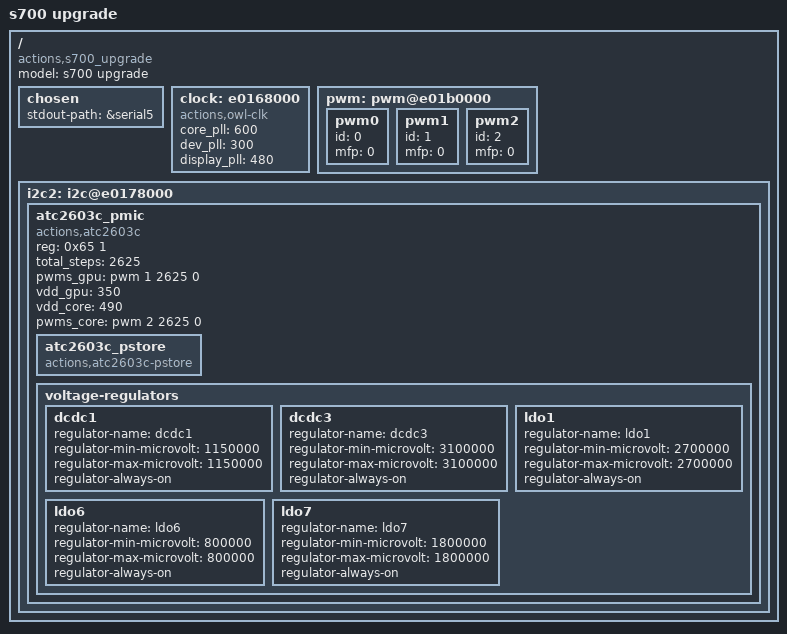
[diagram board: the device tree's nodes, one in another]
/*
 * Copyright (c) 2015 Actions Semi Co., Ltd.
 *
 * SPDX-License-Identifier:	GPL-2.0+
 */

/dts-v1/;

#include "s700.dtsi"

/ {
	model = "s700 upgrade";
	compatible = "actions,s700_upgrade", "actions,s700";

	chosen {
		stdout-path = &serial5;
	};

	clock:e0168000 {
		compatible = "actions,owl-clk";
		core_pll = <600>;
		dev_pll = <300>;
		display_pll = <480>;
	};

	pwm: pwm@e01b0000 {
		pwm0 {
			id = <0>;
			mfp = <0>;
		};

		pwm1 {
			id = <1>;
			mfp = <0>;
		};

		pwm2 {
			id = <2>;
			mfp = <0>;
		};
	};
	i2c2: i2c@e0178000 {
			#address-cells = <1>;
			#size-cells = <1>;
		atc2603c_pmic {
			compatible = "actions,atc2603c";
			reg = <0x65 1>;


			total_steps = <2625>;
			pwms_gpu = <&pwm 1 2625 0>;
			vdd_gpu = <350>;
			vdd_core = <490>;
			pwms_core = <&pwm 2 2625 0>;
			atc2603c_pstore {
					compatible = "actions,atc2603c-pstore";
			};
			voltage-regulators {

			dcdc1: dcdc1 {
				regulator-name = "dcdc1";
				regulator-min-microvolt = <1150000>;
				regulator-max-microvolt = <1150000>;
				regulator-always-on;
			};

			dcdc3: dcdc3 {
				regulator-name = "dcdc3";
				regulator-min-microvolt = <3100000>;
				regulator-max-microvolt = <3100000>;
				regulator-always-on;
			};

			ldo1: ldo1{
				regulator-name = "ldo1";
				regulator-min-microvolt  = <2700000>;
				regulator-max-microvolt = <2700000>;
				regulator-always-on;
			};

			ldo6: ldo6{
				regulator-name = "ldo6";
				regulator-min-microvolt  = <800000>;
				regulator-max-microvolt = <800000>;
				regulator-always-on;
			};

			ldo7: ldo7{
				regulator-name = "ldo7";
				regulator-min-microvolt  = <1800000>;
				regulator-max-microvolt = <1800000>;
				regulator-always-on;
			};


		};


		};
	};
};
